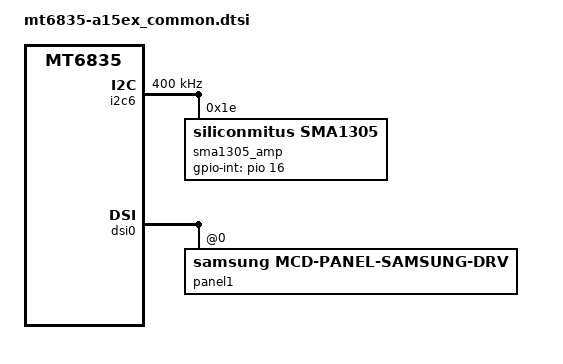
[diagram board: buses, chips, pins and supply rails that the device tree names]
/* Generated by Samsung for MTK vendor board
 * If these files should be changed, then please make a sync with MTK
*/

/* Add Samsung configuration over here */

/ {
	fragment@model {
		target-path = "/";
		__overlay__ {
			sec-audio-sysfs {
				compatible = "samsung,audio-sysfs";
				status = "okay";
				/* audio,no-earjack; */
				/* audio,num-amp = <1>; */
			};
		};
	};
};

&spk {
	status = "disabled";
};

&pio {
	spk_amp_int: spk-amp-int {
		pins_cmd_dat {
			pinmux = <PINMUX_GPIO16__FUNC_GPIO16>;
			slew-rate = <0>;
			bias-disable;
			output-low;
		};
	};

	/* need to check power down timing */
	i2c_amp_bus: i2c-amp-bus {
		pins_cmd_dat {
			pinmux = <PINMUX_GPIO139__FUNC_SCL6>,
				<PINMUX_GPIO140__FUNC_SDA6>;
			slew-rate = <0>;
			bias-disable;
			output-low;
		};
	};
};

&i2c6 {
	status = "okay";
	id = <18>;
	clock-frequency = <400000>;
	#address-cells = <1>;
	#size-cells = <0>;

	pinctrl-names = "default";
	pinctrl-0 = <&i2c_amp_bus>;

	sma1305_amp: sma1305@1e {
		compatible = "siliconmitus,sma1305";
		#sound-dai-cells = <0>;
		reg = <0x1e>;

		pinctrl-names = "default";
		pinctrl-0 = <&spk_amp_int>;

		init-vol = <0x32>;
		/* SPK_4.0W_MODE   : 0x00,
		 * SPK_6.0W_MODE   : 0x01,
		 * RCV_0.1W_MODE   : 0x02,
		 * RCV_0.5W_MODE   : 0x03,
		 */
		spk-rcv-mode = <1>;
		/* EXTERNAL_CLOCK_19_2   : 0x00,
		 * EXTERNAL_CLOCK_24_576 : 0x01,
		 * PLL_CLKIN_MCLK        : 0x02,
		 * PLL_CLKIN_BCLK        : 0x03
		 */
		sys-clk-id = <0x03>;
		sma1305,gpio-int = <&pio 16 0>;
		status = "okay";
	};
};

&sound {
	mediatek,spk-i2s = <3 0>;
	mediatek,speaker-codec {
		sound-dai = <&sma1305_amp>;
	};
};

&accdet {
	accdet-mic-vol = <0x6>;
	/* min_3pole--max_3pole--min_4pole--max_4pole--vol_bias */
	headset-vol-threshold = <0 638 639 2000 2600>;
	/* 0--MD_MAX--VOICE_MAX--UP_MAX--DW_MAX */
	headset-four-key-threshold = <0 165 197 280 550>;
};

&aud_gpio_i2s3_off {
	pins_cmd_dat {
		pinmux = <PINMUX_GPIO44__FUNC_GPIO44>,
			 <PINMUX_GPIO45__FUNC_GPIO45>,
			 <PINMUX_GPIO46__FUNC_GPIO46>;
		slew-rate = <1>;
		bias-disable;
	};
};

&dsi0 {
	panel1@0 {
		compatible = "samsung,mcd-panel-samsung-drv";
	};
};
